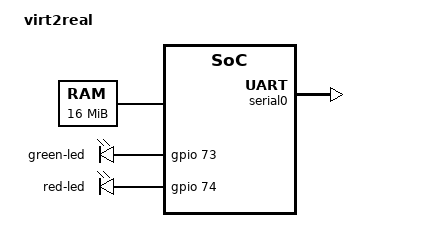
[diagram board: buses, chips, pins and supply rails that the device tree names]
/dts-v1/;

#include "dm365.dtsi"

/ {
	model = "virt2real";

	memory {
		device_type = "memory";
		reg = <0x82000000 0x01000000>;
	};

	soc {
		serial0: serial@1c20000 {
			status = "okay";
		};

		gpio: gpio@1c67000 {
			status = "okay";
		};
	};

	leds {
		compatible = "gpio-leds";

		green_led {
			label = "green-led";
			gpios = <&gpio 73 0>;
		};

		red_led {
			label = "red-led";
			gpios = <&gpio 74 0>;
		};
	};
};
